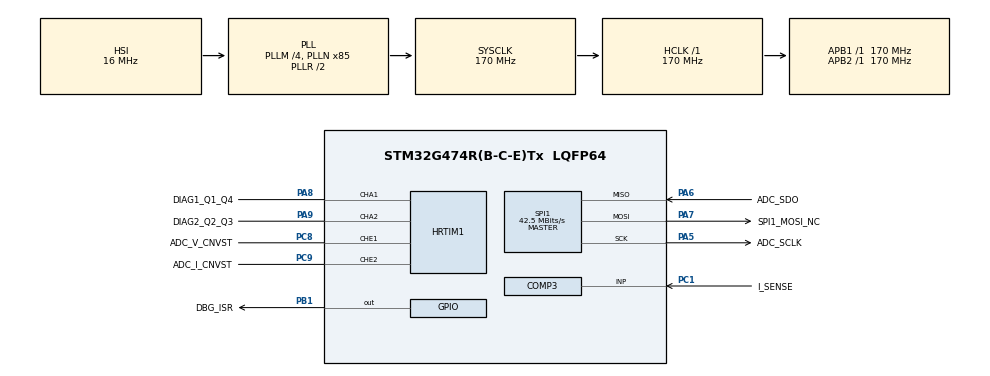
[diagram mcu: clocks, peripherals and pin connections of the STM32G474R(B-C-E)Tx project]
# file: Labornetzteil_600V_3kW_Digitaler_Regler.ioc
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Dma.HRTIM1_E.1.Direction=DMA_MEMORY_TO_PERIPH
Dma.HRTIM1_E.1.EventEnable=DISABLE
Dma.HRTIM1_E.1.Instance=DMA1_Channel1
Dma.HRTIM1_E.1.MemDataAlignment=DMA_MDATAALIGN_HALFWORD
Dma.HRTIM1_E.1.MemInc=DMA_MINC_DISABLE
Dma.HRTIM1_E.1.Mode=DMA_CIRCULAR
Dma.HRTIM1_E.1.PeriphDataAlignment=DMA_PDATAALIGN_HALFWORD
Dma.HRTIM1_E.1.PeriphInc=DMA_PINC_DISABLE
Dma.HRTIM1_E.1.Polarity=HAL_DMAMUX_REQ_GEN_RISING
Dma.HRTIM1_E.1.Priority=DMA_PRIORITY_HIGH
Dma.HRTIM1_E.1.RequestNumber=1
Dma.HRTIM1_E.1.SignalID=NONE
Dma.HRTIM1_E.1.SyncEnable=DISABLE
Dma.HRTIM1_E.1.SyncPolarity=HAL_DMAMUX_SYNC_NO_EVENT
Dma.HRTIM1_E.1.SyncRequestNumber=1
Dma.HRTIM1_E.1.SyncSignalID=NONE
Dma.Request0=SPI1_RX
Dma.Request1=HRTIM1_E
Dma.SPI1_RX.0.Direction=DMA_PERIPH_TO_MEMORY
Dma.SPI1_RX.0.EventEnable=DISABLE
Dma.SPI1_RX.0.Instance=DMA1_Channel2
Dma.SPI1_RX.0.MemDataAlignment=DMA_MDATAALIGN_HALFWORD
Dma.SPI1_RX.0.MemInc=DMA_MINC_ENABLE
Dma.SPI1_RX.0.Mode=DMA_CIRCULAR
Dma.SPI1_RX.0.PeriphDataAlignment=DMA_PDATAALIGN_HALFWORD
Dma.SPI1_RX.0.PeriphInc=DMA_PINC_DISABLE
Dma.SPI1_RX.0.Polarity=HAL_DMAMUX_REQ_GEN_RISING
Dma.SPI1_RX.0.Priority=DMA_PRIORITY_VERY_HIGH
Dma.SPI1_RX.0.RequestNumber=1
Dma.SPI1_RX.0.SignalID=NONE
Dma.SPI1_RX.0.SyncEnable=DISABLE
Dma.SPI1_RX.0.SyncPolarity=HAL_DMAMUX_SYNC_NO_EVENT
Dma.SPI1_RX.0.SyncRequestNumber=1
Dma.SPI1_RX.0.SyncSignalID=NONE
HRTIM1.ADCTrigger_Id1=__NULL
HRTIM1.ADCTrigger_Id10=__NULL
HRTIM1.ADCTrigger_Id2=__NULL
HRTIM1.ADCTrigger_Id3=__NULL
HRTIM1.ADCTrigger_Id4=__NULL
HRTIM1.ADCTrigger_Id5=__NULL
HRTIM1.ADCTrigger_Id6=__NULL
HRTIM1.ADCTrigger_Id7=__NULL
HRTIM1.ADCTrigger_Id8=__NULL
HRTIM1.ADCTrigger_Id9=__NULL
HRTIM1.AutoDelayedMode2-Output_TA1TA2=HRTIM_AUTODELAYEDMODE_REGULAR
HRTIM1.AutoDelayedMode2-Output_TE1TE2=HRTIM_AUTODELAYEDMODE_REGULAR
HRTIM1.BlankingSourceFaultLine5=__NULL
HRTIM1.BurstDMAconfig-Output_TA1TA2=__NULL
HRTIM1.BurstDMAconfig-Output_TE1TE2=__NULL
HRTIM1.BurstMode-Output_TA1TA2=HRTIM_TIMERBURSTMODE_MAINTAINCLOCK
HRTIM1.BurstMode-Output_TE1TE2=HRTIM_TIMERBURSTMODE_MAINTAINCLOCK
HRTIM1.BurstModeEntryDelayed1-Output_TA1TA2=HRTIM_OUTPUTBURSTMODEENTRY_REGULAR
HRTIM1.BurstModeEntryDelayed1-Output_TE1TE2=HRTIM_OUTPUTBURSTMODEENTRY_REGULAR
HRTIM1.BurstModeEntryDelayed2-Output_TA1TA2=HRTIM_OUTPUTBURSTMODEENTRY_REGULAR
HRTIM1.BurstModeEntryDelayed2-Output_TE1TE2=HRTIM_OUTPUTBURSTMODEENTRY_REGULAR
HRTIM1.CaptureUnit1-Output_TA1TA2=__NULL
HRTIM1.CaptureUnit1-Output_TE1TE2=__NULL
HRTIM1.CaptureUnit2-Output_TA1TA2=__NULL
HRTIM1.CaptureUnit2-Output_TE1TE2=__NULL
HRTIM1.ChopperModeEnable1-Output_TA1TA2=HRTIM_OUTPUTCHOPPERMODE_DISABLED
HRTIM1.ChopperModeEnable1-Output_TE1TE2=HRTIM_OUTPUTCHOPPERMODE_DISABLED
HRTIM1.ChopperModeEnable2-Output_TA1TA2=HRTIM_OUTPUTCHOPPERMODE_DISABLED
HRTIM1.ChopperModeEnable2-Output_TE1TE2=HRTIM_OUTPUTCHOPPERMODE_DISABLED
HRTIM1.ChopperModeconfig-Output_TA1TA2=__NULL
HRTIM1.ChopperModeconfig-Output_TE1TE2=__NULL
HRTIM1.CompareUnit1-Output_TA1TA2=HRTIM_COMPAREUNIT_1
HRTIM1.CompareUnit1-Output_TE1TE2=HRTIM_COMPAREUNIT_1
HRTIM1.CompareUnit2-Output_TA1TA2=HRTIM_COMPAREUNIT_2
HRTIM1.CompareUnit2-Output_TE1TE2=HRTIM_COMPAREUNIT_2
HRTIM1.CompareUnit3-Output_TA1TA2=HRTIM_COMPAREUNIT_3
HRTIM1.CompareUnit3-Output_TE1TE2=HRTIM_COMPAREUNIT_3
HRTIM1.CompareUnit4-Output_TA1TA2=__NULL
HRTIM1.CompareUnit4-Output_TE1TE2=__NULL
HRTIM1.CompareValue1-Output_TA1TA2=163
HRTIM1.CompareValue1-Output_TE1TE2=22304
HRTIM1.CompareValue2-Output_TA1TA2=27200
HRTIM1.CompareValue2-Output_TE1TE2=26656
HRTIM1.CompareValue3-Output_TA1TA2=27363
HRTIM1.CompareValue3-Output_TE1TE2=30067
HRTIM1.Configuration_TA=Waveform
HRTIM1.Configuration_TE=Waveform
HRTIM1.CounterFaultLine5=0
HRTIM1.DACSynchro-Output_TA1TA2=HRTIM_DACSYNC_NONE
HRTIM1.DACSynchro-Output_TE1TE2=HRTIM_DACSYNC_NONE
HRTIM1.DMADstAddress-Output_TE1TE2=(uint32_t)&SPI1->DR
HRTIM1.DMARequests1-Output_TE1TE2=HRTIM_TIM_DMA_CMP2
HRTIM1.DMARequests2-Output_TE1TE2=HRTIM_TIM_DMA_CMP3
HRTIM1.DMASize-Output_TE1TE2=0x1
HRTIM1.DMASrcAddress-Output_TE1TE2=(uint32_t)&pwr_spi_dummy
HRTIM1.DeadTimeInsertion-Output_TA1TA2=HRTIM_TIMDEADTIMEINSERTION_DISABLED
HRTIM1.DeadTimeInsertion-Output_TE1TE2=HRTIM_TIMDEADTIMEINSERTION_DISABLED
HRTIM1.Deadtimeconfig-Output_TA1TA2=__NULL
HRTIM1.Deadtimeconfig-Output_TE1TE2=__NULL
HRTIM1.DelayedProtectionMode-Output_TA1TA2=HRTIM_TIMER_A_B_C_DELAYEDPROTECTION_DISABLED
HRTIM1.DelayedProtectionMode-Output_TE1TE2=HRTIM_TIMER_D_E_DELAYEDPROTECTION_DISABLED
HRTIM1.DualChannelDacEnableFake_TA-Output_TA1TA2=HRTIM_TIMER_DCDE_DISABLED
HRTIM1.DualChannelDacEnableFake_TE-Output_TE1TE2=HRTIM_TIMER_DCDE_DISABLED
HRTIM1.Enable=HRTIM_BURSTMODECTL_DISABLED
HRTIM1.Enable_FaultLine5=HRTIM_FAULTMODECTL_ENABLED
HRTIM1.Event1-Output_TA1TA2=__NULL
HRTIM1.Event1-Output_TE1TE2=__NULL
HRTIM1.Event10-Output_TA1TA2=__NULL
HRTIM1.Event10-Output_TE1TE2=__NULL
HRTIM1.Event2-Output_TA1TA2=__NULL
HRTIM1.Event2-Output_TE1TE2=__NULL
HRTIM1.Event3-Output_TA1TA2=__NULL
HRTIM1.Event3-Output_TE1TE2=__NULL
HRTIM1.Event4-Output_TA1TA2=__NULL
HRTIM1.Event4-Output_TE1TE2=__NULL
HRTIM1.Event5-Output_TA1TA2=__NULL
HRTIM1.Event5-Output_TE1TE2=__NULL
HRTIM1.Event6-Output_TA1TA2=__NULL
HRTIM1.Event6-Output_TE1TE2=__NULL
HRTIM1.Event7-Output_TA1TA2=__NULL
HRTIM1.Event7-Output_TE1TE2=__NULL
HRTIM1.Event8-Output_TA1TA2=__NULL
HRTIM1.Event8-Output_TE1TE2=__NULL
HRTIM1.Event9-Output_TA1TA2=__NULL
HRTIM1.Event9-Output_TE1TE2=__NULL
HRTIM1.EventEnableA-Output_TA1TA2=__NULL
HRTIM1.EventEnableA-Output_TE1TE2=__NULL
HRTIM1.Event_EEV1=__NULL
HRTIM1.Event_EEV10=__NULL
HRTIM1.Event_EEV2=__NULL
HRTIM1.Event_EEV3=__NULL
HRTIM1.Event_EEV4=__NULL
HRTIM1.Event_EEV5=__NULL
HRTIM1.Event_EEV6=__NULL
HRTIM1.Event_EEV7=__NULL
HRTIM1.Event_EEV8=__NULL
HRTIM1.Event_EEV9=__NULL
HRTIM1.FaultEnable_Source1-Output_TA1TA2=HRTIM_TIMFAULTENABLE_FAULT5
HRTIM1.FaultLevel1-Output_TA1TA2=HRTIM_OUTPUTFAULTLEVEL_INACTIVE
HRTIM1.FaultLevel1-Output_TE1TE2=HRTIM_OUTPUTFAULTLEVEL_NONE
HRTIM1.FaultLevel2-Output_TA1TA2=HRTIM_OUTPUTFAULTLEVEL_INACTIVE
HRTIM1.FaultLevel2-Output_TE1TE2=HRTIM_OUTPUTFAULTLEVEL_NONE
HRTIM1.FaultLock-Output_TA1TA2=HRTIM_TIMFAULTLOCK_READONLY
HRTIM1.FaultLock-Output_TE1TE2=HRTIM_TIMFAULTLOCK_READWRITE
HRTIM1.Fault_Line1=__NULL
HRTIM1.Fault_Line2=__NULL
HRTIM1.Fault_Line3=__NULL
HRTIM1.Fault_Line4=__NULL
HRTIM1.Fault_Line5=HRTIM_FAULT_5
HRTIM1.Fault_Line6=__NULL
HRTIM1.Filter_FaultLine5=HRTIM_FAULTFILTER_NONE
HRTIM1.GreaterCMP1_TA=HRTIM_TIMERGTCMP1_EQUAL
HRTIM1.GreaterCMP1_TE=HRTIM_TIMERGTCMP1_EQUAL
HRTIM1.GreaterCMP3_TA=HRTIM_TIMERGTCMP3_EQUAL
HRTIM1.GreaterCMP3_TE=HRTIM_TIMERGTCMP3_EQUAL
HRTIM1.HRTIMInterruptResquests1=HRTIM_IT_NONE
HRTIM1.HRTIMInterruptResquests2=HRTIM_IT_NONE
HRTIM1.HRTIMInterruptResquests3=HRTIM_IT_NONE
HRTIM1.HRTIMInterruptResquests4=HRTIM_IT_NONE
HRTIM1.HRTIMInterruptResquests5=HRTIM_IT_NONE
HRTIM1.HRTIMInterruptResquests6=HRTIM_IT_NONE
HRTIM1.HRTIMInterruptResquests7=HRTIM_IT_NONE
HRTIM1.HRTIMInterruptResquests8=HRTIM_IT_NONE
HRTIM1.HRTIMInterruptResquests9=HRTIM_IT_NONE
HRTIM1.IdleLevel1-Output_TA1TA2=HRTIM_OUTPUTIDLELEVEL_INACTIVE
HRTIM1.IdleLevel1-Output_TE1TE2=HRTIM_OUTPUTIDLELEVEL_INACTIVE
HRTIM1.IdleLevel2-Output_TA1TA2=HRTIM_OUTPUTIDLELEVEL_INACTIVE
HRTIM1.IdleLevel2-Output_TE1TE2=HRTIM_OUTPUTIDLELEVEL_INACTIVE
HRTIM1.IdleMode1-Output_TA1TA2=HRTIM_OUTPUTIDLEMODE_NONE
HRTIM1.IdleMode1-Output_TE1TE2=HRTIM_OUTPUTIDLEMODE_NONE
HRTIM1.IdleMode2-Output_TA1TA2=HRTIM_OUTPUTIDLEMODE_NONE
HRTIM1.IdleMode2-Output_TE1TE2=HRTIM_OUTPUTIDLEMODE_NONE
HRTIM1.InterleavedMode-Output_TA1TA2=HRTIM_INTERLEAVED_MODE_DISABLED
HRTIM1.InterleavedMode-Output_TE1TE2=HRTIM_INTERLEAVED_MODE_DISABLED
HRTIM1.Lock_FaultLine5=HRTIM_FAULTLOCK_READWRITE
HRTIM1.ModeTimeBase-Output_TA1TA2=HRTIM_MODE_CONTINUOUS
HRTIM1.ModeTimeBase-Output_TE1TE2=HRTIM_MODE_CONTINUOUS
HRTIM1.NumberDMARequests_TA=0
HRTIM1.NumberDMARequests_TE=2
HRTIM1.NumberFaultEnable-Output_TA1TA2=1
HRTIM1.NumberFaultEnable-Output_TE1TE2=0
HRTIM1.NumberInterruptRequests-Output_TA1TA2=0
HRTIM1.NumberInterruptRequests-Output_TE1TE2=0
HRTIM1.NumberResetSource1-Output_TA1TA2=1
HRTIM1.NumberResetSource1-Output_TE1TE2=1
HRTIM1.NumberResetSource2_TA=1
HRTIM1.NumberResetSource2_TE=1
HRTIM1.NumberResetTrigger-Output_TA1TA2=0
HRTIM1.NumberResetTrigger-Output_TE1TE2=0
HRTIM1.NumberSetSource1-Output_TA1TA2=1
HRTIM1.NumberSetSource1-Output_TE1TE2=1
HRTIM1.NumberSetSource2_TA=1
HRTIM1.NumberSetSource2_TE=1
HRTIM1.NumberUpdateTrigger-Output_TA1TA2=0
HRTIM1.NumberUpdateTrigger-Output_TE1TE2=0
HRTIM1.Output1-Output_TA1TA2=HRTIM_OUTPUT_TA1
HRTIM1.Output1-Output_TE1TE2=HRTIM_OUTPUT_TE1
HRTIM1.Output2-Output_TA1TA2=HRTIM_OUTPUT_TA2
HRTIM1.Output2-Output_TE1TE2=HRTIM_OUTPUT_TE2
HRTIM1.Periode_TA=54400
HRTIM1.Periode_TE=54400
HRTIM1.Polarity1-Output_TA1TA2=HRTIM_OUTPUTPOLARITY_HIGH
HRTIM1.Polarity1-Output_TE1TE2=HRTIM_OUTPUTPOLARITY_HIGH
HRTIM1.Polarity2-Output_TA1TA2=HRTIM_OUTPUTPOLARITY_HIGH
HRTIM1.Polarity2-Output_TE1TE2=HRTIM_OUTPUTPOLARITY_HIGH
HRTIM1.Polarity_FaultLine5=HRTIM_FAULTPOLARITY_HIGH
HRTIM1.PreloadEnable-Output_TA1TA2=HRTIM_PRELOAD_ENABLED
HRTIM1.PreloadEnable-Output_TE1TE2=HRTIM_PRELOAD_ENABLED
HRTIM1.PrescalerFault=HRTIM_FAULTPRESCALER_DIV1
HRTIM1.PrescalerRatio_TA=HRTIM_PRESCALERRATIO_MUL32
HRTIM1.PrescalerRatio_TE=HRTIM_PRESCALERRATIO_MUL32
HRTIM1.PushPull-Output_TA1TA2=HRTIM_TIMPUSHPULLMODE_DISABLED
HRTIM1.PushPull-Output_TE1TE2=HRTIM_TIMPUSHPULLMODE_DISABLED
HRTIM1.ReSyncUpdate-Output_TA1TA2=HRTIM_TIMERESYNC_UPDATE_UNCONDITIONAL
HRTIM1.ReSyncUpdate-Output_TE1TE2=HRTIM_TIMERESYNC_UPDATE_UNCONDITIONAL
HRTIM1.RepetitionUpdate-Output_TA1TA2=HRTIM_UPDATEONREPETITION_DISABLED
HRTIM1.RepetitionUpdate-Output_TE1TE2=HRTIM_UPDATEONREPETITION_DISABLED
HRTIM1.ResetModeFaultLine5=HRTIM_FAULTCOUNTERRST_UNCONDITIONAL
HRTIM1.ResetOnSync-Output_TA1TA2=HRTIM_SYNCRESET_DISABLED
HRTIM1.ResetOnSync-Output_TE1TE2=HRTIM_SYNCRESET_DISABLED
HRTIM1.ResetOutput1_Source1-Output_TA1TA2=HRTIM_OUTPUTRESET_TIMCMP1
HRTIM1.ResetOutput1_Source1-Output_TE1TE2=HRTIM_OUTPUTRESET_TIMCMP2
HRTIM1.ResetOutput2_Source1-Output_TA1TA2=HRTIM_OUTPUTRESET_TIMCMP3
HRTIM1.ResetOutput2_Source1-Output_TE1TE2=HRTIM_OUTPUTRESET_TIMCMP3
HRTIM1.ResetUpdate-Output_TA1TA2=HRTIM_TIMUPDATEONRESET_ENABLED
HRTIM1.ResetUpdate-Output_TE1TE2=HRTIM_TIMUPDATEONRESET_ENABLED
HRTIM1.SetOutput1_Source1-Output_TA1TA2=HRTIM_OUTPUTSET_TIMPER
HRTIM1.SetOutput1_Source1-Output_TE1TE2=HRTIM_OUTPUTSET_TIMCMP1
HRTIM1.SetOutput2_Source1-Output_TA1TA2=HRTIM_OUTPUTSET_TIMCMP2
HRTIM1.SetOutput2_Source1-Output_TE1TE2=HRTIM_OUTPUTSET_TIMCMP1
HRTIM1.Source_FaultLine5=HRTIM_FAULTSOURCE_INTERNAL
HRTIM1.StartOnSync-Output_TA1TA2=HRTIM_SYNCSTART_DISABLED
HRTIM1.StartOnSync-Output_TE1TE2=HRTIM_SYNCSTART_DISABLED
HRTIM1.SwapA=__NULL
HRTIM1.SwapE=__NULL
HRTIM1.SyncOptions=HRTIM_SYNCOPTION_NONE
HRTIM1.TimerIdx-Output_TA1TA2=HRTIM_TIMERINDEX_TIMER_A
HRTIM1.TimerIdx-Output_TE1TE2=HRTIM_TIMERINDEX_TIMER_E
HRTIM1.TrigHalf_TA=HRTIM_TIMERTRIGHALF_DISABLED
HRTIM1.TrigHalf_TE=HRTIM_TIMERTRIGHALF_DISABLED
HRTIM1.UpDownMode-Output_TA1TA2=HRTIM_TIMERUPDOWNMODE_UP
HRTIM1.UpDownMode-Output_TE1TE2=HRTIM_TIMERUPDOWNMODE_UP
HRTIM1.UpdateGating-Output_TA1TA2=HRTIM_UPDATEGATING_INDEPENDENT
HRTIM1.UpdateGating-Output_TE1TE2=HRTIM_UPDATEGATING_INDEPENDENT
Mcu.Family=STM32G4
Mcu.Name=STM32G474R(B-C-E)Tx
Mcu.Package=LQFP64
NVIC.DMA1_Channel1_IRQn=true\:2\:0\:false\:false\:true\:false\:true\:true
NVIC.DMA1_Channel2_IRQn=true\:0\:0\:false\:false\:false\:false\:false\:true
NVIC.PriorityGroup=NVIC_PRIORITYGROUP_4
PA13.Mode=Serial_Wire
PA13.Signal=SYS_JTMS-SWDIO
PA14.Mode=Serial_Wire
PA14.Signal=SYS_JTCK-SWCLK
PA5.GPIO_Label=ADC_SCLK
PA5.GPIO_Speed=GPIO_SPEED_FREQ_VERY_HIGH
PA5.Mode=Full_Duplex_Master
PA5.Signal=SPI1_SCK
PA6.GPIO_Label=ADC_SDO
PA6.GPIO_PuPd=GPIO_PULLUP
PA6.GPIO_Speed=GPIO_SPEED_FREQ_VERY_HIGH
PA6.Mode=Full_Duplex_Master
PA6.Signal=SPI1_MISO
PA7.GPIO_Label=SPI1_MOSI_NC
PA7.Mode=Full_Duplex_Master
PA7.Signal=SPI1_MOSI
PA8.GPIO_Label=DIAG1_Q1_Q4
PA8.GPIO_Speed=GPIO_SPEED_FREQ_VERY_HIGH
PA8.Mode=Output_TA1TA2
PA8.Signal=HRTIM1_CHA1
PA9.GPIO_Label=DIAG2_Q2_Q3
PA9.GPIO_Speed=GPIO_SPEED_FREQ_VERY_HIGH
PA9.Mode=Output_TA1TA2
PA9.Signal=HRTIM1_CHA2
PB1.GPIO_Label=DBG_ISR
PB1.GPIO_Speed=GPIO_SPEED_FREQ_VERY_HIGH
PB1.Signal=GPIO_Output
PC1.GPIO_Label=I_SENSE
PC1.Mode=INP
PC1.Signal=COMP3_INP
PC8.GPIO_Label=ADC_V_CNVST
PC8.GPIO_Speed=GPIO_SPEED_FREQ_VERY_HIGH
PC8.Mode=Output_TE1TE2
PC8.Signal=HRTIM1_CHE1
PC9.GPIO_Label=ADC_I_CNVST
PC9.GPIO_Speed=GPIO_SPEED_FREQ_VERY_HIGH
PC9.Mode=Output_TE1TE2
PC9.Signal=HRTIM1_CHE2
ProjectManager.HeapSize=0x200
ProjectManager.StackSize=0x400
ProjectManager.TargetToolchain=STM32CubeIDE
RCC.ADC12Freq_Value=170000000
RCC.ADC345Freq_Value=170000000
RCC.AHBFreq_Value=170000000
RCC.APB1Freq_Value=170000000
RCC.APB1TimFreq_Value=170000000
RCC.APB2Freq_Value=170000000
RCC.APB2TimFreq_Value=170000000
RCC.CortexFreq_Value=170000000
RCC.EXTERNAL_CLOCK_VALUE=12288000
RCC.HCLKFreq_Value=170000000
RCC.HSE_VALUE=8000000
RCC.HSI48_VALUE=48000000
RCC.HSI_VALUE=16000000
RCC.LSE_VALUE=32768
RCC.PLLM=RCC_PLLM_DIV4
RCC.PLLN=85
RCC.PLLSourceVirtual=RCC_PLLSOURCE_HSI
RCC.SYSCLKFreq_VALUE=170000000
RCC.SYSCLKSource=RCC_SYSCLKSOURCE_PLLCLK
RCC.USBFreq_Value=170000000
RCC.VCOOutputFreq_Value=340000000
SPI1.BaudRatePrescaler=SPI_BAUDRATEPRESCALER_4
SPI1.CLKPhase=SPI_PHASE_2EDGE
SPI1.CLKPolarity=SPI_POLARITY_LOW
SPI1.CRCCalculation=SPI_CRCCALCULATION_DISABLE
SPI1.CalculateBaudRate=42.5 MBits/s
SPI1.DataSize=SPI_DATASIZE_16BIT
SPI1.Direction=SPI_DIRECTION_2LINES
SPI1.FirstBit=SPI_FIRSTBIT_MSB
SPI1.Mode=SPI_MODE_MASTER
SPI1.NSS=SPI_NSS_SOFT
SPI1.TIMode=SPI_TIMODE_DISABLE
SPI1.VirtualType=VM_MASTER
VP_COMP3_VS_DAC3OUT1.Mode=INM_DAC3OUT1
VP_DAC3_VS_DACI1.Mode=DAC_OUT1_Int
VP_SYS_VS_DBSignals.Mode=DisableDeadBatterySignals
board=custom

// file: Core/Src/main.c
/* USER CODE BEGIN Header */
/**
  ******************************************************************************
  * @file           : main.c
  * @brief          : Main program body
  ******************************************************************************
  * @attention
  *
  * Copyright (c) 2026 STMicroelectronics.
  * All rights reserved.
  *
  * This software is licensed under terms that can be found in the LICENSE file
  * in the root directory of this software component.
  * If no LICENSE file comes with this software, it is provided AS-IS.
  *
  ******************************************************************************
  */
/* USER CODE END Header */
#include "main.h"

/* USER CODE BEGIN Includes */
#include "pwr_ctrl.h"   /* also declares pwr_spi_dummy, used in MX_HRTIM1_Init() */
/* USER CODE END Includes */

COMP_HandleTypeDef hcomp3;

DAC_HandleTypeDef hdac3;

HRTIM_HandleTypeDef hhrtim1;
DMA_HandleTypeDef hdma_hrtim1_e;

SPI_HandleTypeDef hspi1;
DMA_HandleTypeDef hdma_spi1_rx;

void SystemClock_Config(void);
static void MX_GPIO_Init(void);
static void MX_DMA_Init(void);
static void MX_HRTIM1_Init(void);
static void MX_SPI1_Init(void);
static void MX_COMP3_Init(void);
static void MX_DAC3_Init(void);

int main(void)
{

  /* MCU Configuration--------------------------------------------------------*/

  /* Reset of all peripherals, Initializes the Flash interface and the Systick. */
  HAL_Init();

  /* Configure the system clock */
  SystemClock_Config();

  /* Initialize all configured peripherals */
  MX_GPIO_Init();
  MX_DMA_Init();
  MX_HRTIM1_Init();
  MX_SPI1_Init();
  MX_COMP3_Init();
  MX_DAC3_Init();
  /* USER CODE BEGIN 2 */

  /* Hardware OCP (DAC3 -> COMP3 -> HRTIM FLT5) armed at PWR_OCP_HW_A,
   * ADC recalibration (~0.6 s), DMA chain start, HRTIM counters start.
   * Afterwards both ADCs are sampled every period, the bridge stays OFF. */
  pwr_init(&hhrtim1, &hspi1, &hcomp3, &hdac3);

  pwr_set_current(1.0f);    /* [A] current limit                          */
  pwr_set_voltage(5.0f);    /* [V] ramps at PWR_VREF_SLEW_V_PER_S         */

  /* Bring-up: enable the bridge deliberately (debugger or command), e.g.*/
  pwr_output_on();

  /* USER CODE END 2 */

  /* Infinite loop */
  while (1)
  {

    /* USER CODE BEGIN 3 */
    const pwr_status_t *st = pwr_status();
    if (st->state == PWR_STATE_FAULT)
    {
      /* report st->fault (PWR_FAULT_x), then e.g.:
       * pwr_clear_fault(); (void)pwr_output_on();                          */
    }
  }
  /* USER CODE END 3 */
}

void SystemClock_Config(void)
{
  RCC_OscInitTypeDef RCC_OscInitStruct = {0};
  RCC_ClkInitTypeDef RCC_ClkInitStruct = {0};

  /** Configure the main internal regulator output voltage
  */
  HAL_PWREx_ControlVoltageScaling(PWR_REGULATOR_VOLTAGE_SCALE1_BOOST);

  /** Initializes the RCC Oscillators according to the specified parameters
  * in the RCC_OscInitTypeDef structure.
  */
  RCC_OscInitStruct.OscillatorType = RCC_OSCILLATORTYPE_HSI;
  RCC_OscInitStruct.HSIState = RCC_HSI_ON;
  RCC_OscInitStruct.HSICalibrationValue = RCC_HSICALIBRATION_DEFAULT;
  RCC_OscInitStruct.PLL.PLLState = RCC_PLL_ON;
  RCC_OscInitStruct.PLL.PLLSource = RCC_PLLSOURCE_HSI;
  RCC_OscInitStruct.PLL.PLLM = RCC_PLLM_DIV4;
  RCC_OscInitStruct.PLL.PLLN = 85;
  RCC_OscInitStruct.PLL.PLLP = RCC_PLLP_DIV2;
  RCC_OscInitStruct.PLL.PLLQ = RCC_PLLQ_DIV2;
  RCC_OscInitStruct.PLL.PLLR = RCC_PLLR_DIV2;
  if (HAL_RCC_OscConfig(&RCC_OscInitStruct) != HAL_OK)
  {
    Error_Handler();
  }

  /** Initializes the CPU, AHB and APB buses clocks
  */
  RCC_ClkInitStruct.ClockType = RCC_CLOCKTYPE_HCLK|RCC_CLOCKTYPE_SYSCLK
                              |RCC_CLOCKTYPE_PCLK1|RCC_CLOCKTYPE_PCLK2;
  RCC_ClkInitStruct.SYSCLKSource = RCC_SYSCLKSOURCE_PLLCLK;
  RCC_ClkInitStruct.AHBCLKDivider = RCC_SYSCLK_DIV1;
  RCC_ClkInitStruct.APB1CLKDivider = RCC_HCLK_DIV1;
  RCC_ClkInitStruct.APB2CLKDivider = RCC_HCLK_DIV1;

  if (HAL_RCC_ClockConfig(&RCC_ClkInitStruct, FLASH_LATENCY_4) != HAL_OK)
  {
    Error_Handler();
  }
}

static void MX_COMP3_Init(void)
{

  hcomp3.Instance = COMP3;
  hcomp3.Init.InputPlus = COMP_INPUT_PLUS_IO2;
  hcomp3.Init.InputMinus = COMP_INPUT_MINUS_DAC3_CH1;
  hcomp3.Init.OutputPol = COMP_OUTPUTPOL_NONINVERTED;
  hcomp3.Init.Hysteresis = COMP_HYSTERESIS_NONE;
  hcomp3.Init.BlankingSrce = COMP_BLANKINGSRC_NONE;
  hcomp3.Init.TriggerMode = COMP_TRIGGERMODE_NONE;
  if (HAL_COMP_Init(&hcomp3) != HAL_OK)
  {
    Error_Handler();
  }

}

static void MX_DAC3_Init(void)
{

  DAC_ChannelConfTypeDef sConfig = {0};

  /** DAC Initialization
  */
  hdac3.Instance = DAC3;
  if (HAL_DAC_Init(&hdac3) != HAL_OK)
  {
    Error_Handler();
  }

  /** DAC channel OUT1 config
  */
  sConfig.DAC_HighFrequency = DAC_HIGH_FREQUENCY_INTERFACE_MODE_AUTOMATIC;
  sConfig.DAC_DMADoubleDataMode = DISABLE;
  sConfig.DAC_SignedFormat = DISABLE;
  sConfig.DAC_SampleAndHold = DAC_SAMPLEANDHOLD_DISABLE;
  sConfig.DAC_Trigger = DAC_TRIGGER_NONE;
  sConfig.DAC_Trigger2 = DAC_TRIGGER_NONE;
  sConfig.DAC_OutputBuffer = DAC_OUTPUTBUFFER_DISABLE;
  sConfig.DAC_ConnectOnChipPeripheral = DAC_CHIPCONNECT_INTERNAL;
  sConfig.DAC_UserTrimming = DAC_TRIMMING_FACTORY;
  if (HAL_DAC_ConfigChannel(&hdac3, &sConfig, DAC_CHANNEL_1) != HAL_OK)
  {
    Error_Handler();
  }

}

static void MX_HRTIM1_Init(void)
{

  HRTIM_FaultBlankingCfgTypeDef pFaultBlkCfg = {0};
  HRTIM_FaultCfgTypeDef pFaultCfg = {0};
  HRTIM_TimeBaseCfgTypeDef pTimeBaseCfg = {0};
  HRTIM_TimerCtlTypeDef pTimerCtl = {0};
  HRTIM_TimerCfgTypeDef pTimerCfg = {0};
  HRTIM_CompareCfgTypeDef pCompareCfg = {0};
  HRTIM_OutputCfgTypeDef pOutputCfg = {0};

  hhrtim1.Instance = HRTIM1;
  hhrtim1.Init.HRTIMInterruptResquests = HRTIM_IT_NONE;
  hhrtim1.Init.SyncOptions = HRTIM_SYNCOPTION_NONE;
  if (HAL_HRTIM_Init(&hhrtim1) != HAL_OK)
  {
    Error_Handler();
  }
  if (HAL_HRTIM_DLLCalibrationStart(&hhrtim1, HRTIM_CALIBRATIONRATE_3) != HAL_OK)
  {
    Error_Handler();
  }
  if (HAL_HRTIM_PollForDLLCalibration(&hhrtim1, 10) != HAL_OK)
  {
    Error_Handler();
  }
  if (HAL_HRTIM_FaultPrescalerConfig(&hhrtim1, HRTIM_FAULTPRESCALER_DIV1) != HAL_OK)
  {
    Error_Handler();
  }
  pFaultBlkCfg.Threshold = 0;
  pFaultBlkCfg.ResetMode = HRTIM_FAULTCOUNTERRST_UNCONDITIONAL;
  if (HAL_HRTIM_FaultCounterConfig(&hhrtim1, HRTIM_FAULT_5, &pFaultBlkCfg) != HAL_OK)
  {
    Error_Handler();
  }
  if (HAL_HRTIM_FaultCounterConfig(&hhrtim1, HRTIM_FAULT_5, &pFaultBlkCfg) != HAL_OK)
  {
    Error_Handler();
  }
  pFaultCfg.Source = HRTIM_FAULTSOURCE_INTERNAL;
  pFaultCfg.Polarity = HRTIM_FAULTPOLARITY_HIGH;
  pFaultCfg.Filter = HRTIM_FAULTFILTER_NONE;
  pFaultCfg.Lock = HRTIM_FAULTLOCK_READWRITE;
  if (HAL_HRTIM_FaultConfig(&hhrtim1, HRTIM_FAULT_5, &pFaultCfg) != HAL_OK)
  {
    Error_Handler();
  }
  HAL_HRTIM_FaultModeCtl(&hhrtim1, HRTIM_FAULT_5, HRTIM_FAULTMODECTL_ENABLED);
  pTimeBaseCfg.Period = 54400;
  pTimeBaseCfg.RepetitionCounter = 0x00;
  pTimeBaseCfg.PrescalerRatio = HRTIM_PRESCALERRATIO_MUL32;
  pTimeBaseCfg.Mode = HRTIM_MODE_CONTINUOUS;
  if (HAL_HRTIM_TimeBaseConfig(&hhrtim1, HRTIM_TIMERINDEX_TIMER_A, &pTimeBaseCfg) != HAL_OK)
  {
    Error_Handler();
  }
  pTimerCtl.UpDownMode = HRTIM_TIMERUPDOWNMODE_UP;
  pTimerCtl.TrigHalf = HRTIM_TIMERTRIGHALF_DISABLED;
  pTimerCtl.GreaterCMP3 = HRTIM_TIMERGTCMP3_EQUAL;
  pTimerCtl.GreaterCMP1 = HRTIM_TIMERGTCMP1_EQUAL;
  pTimerCtl.DualChannelDacEnable = HRTIM_TIMER_DCDE_DISABLED;
  if (HAL_HRTIM_WaveformTimerControl(&hhrtim1, HRTIM_TIMERINDEX_TIMER_A, &pTimerCtl) != HAL_OK)
  {
    Error_Handler();
  }
  pTimerCfg.InterruptRequests = HRTIM_TIM_IT_NONE;
  pTimerCfg.DMARequests = HRTIM_TIM_DMA_NONE;
  pTimerCfg.DMASrcAddress = 0x0000;
  pTimerCfg.DMADstAddress = 0x0000;
  pTimerCfg.DMASize = 0x1;
  pTimerCfg.HalfModeEnable = HRTIM_HALFMODE_DISABLED;
  pTimerCfg.InterleavedMode = HRTIM_INTERLEAVED_MODE_DISABLED;
  pTimerCfg.StartOnSync = HRTIM_SYNCSTART_DISABLED;
  pTimerCfg.ResetOnSync = HRTIM_SYNCRESET_DISABLED;
  pTimerCfg.DACSynchro = HRTIM_DACSYNC_NONE;
  pTimerCfg.PreloadEnable = HRTIM_PRELOAD_ENABLED;
  pTimerCfg.UpdateGating = HRTIM_UPDATEGATING_INDEPENDENT;
  pTimerCfg.BurstMode = HRTIM_TIMERBURSTMODE_MAINTAINCLOCK;
  pTimerCfg.RepetitionUpdate = HRTIM_UPDATEONREPETITION_DISABLED;
  pTimerCfg.PushPull = HRTIM_TIMPUSHPULLMODE_DISABLED;
  pTimerCfg.FaultEnable = HRTIM_TIMFAULTENABLE_FAULT5;
  pTimerCfg.FaultLock = HRTIM_TIMFAULTLOCK_READONLY;
  pTimerCfg.DeadTimeInsertion = HRTIM_TIMDEADTIMEINSERTION_DISABLED;
  pTimerCfg.DelayedProtectionMode = HRTIM_TIMER_A_B_C_DELAYEDPROTECTION_DISABLED;
  pTimerCfg.UpdateTrigger = HRTIM_TIMUPDATETRIGGER_NONE;
  pTimerCfg.ResetTrigger = HRTIM_TIMRESETTRIGGER_NONE;
  pTimerCfg.ResetUpdate = HRTIM_TIMUPDATEONRESET_ENABLED;
  pTimerCfg.ReSyncUpdate = HRTIM_TIMERESYNC_UPDATE_UNCONDITIONAL;
  if (HAL_HRTIM_WaveformTimerConfig(&hhrtim1, HRTIM_TIMERINDEX_TIMER_A, &pTimerCfg) != HAL_OK)
  {
    Error_Handler();
  }
  pTimerCfg.DMARequests = HRTIM_TIM_DMA_CMP2|HRTIM_TIM_DMA_CMP3;
  pTimerCfg.DMASrcAddress = (uint32_t)&pwr_spi_dummy;
  pTimerCfg.DMADstAddress = (uint32_t)&SPI1->DR;
  pTimerCfg.FaultEnable = HRTIM_TIMFAULTENABLE_NONE;
  pTimerCfg.FaultLock = HRTIM_TIMFAULTLOCK_READWRITE;
  pTimerCfg.DelayedProtectionMode = HRTIM_TIMER_D_E_DELAYEDPROTECTION_DISABLED;
  if (HAL_HRTIM_WaveformTimerConfig(&hhrtim1, HRTIM_TIMERINDEX_TIMER_E, &pTimerCfg) != HAL_OK)
  {
    Error_Handler();
  }
  pCompareCfg.CompareValue = 163;
  if (HAL_HRTIM_WaveformCompareConfig(&hhrtim1, HRTIM_TIMERINDEX_TIMER_A, HRTIM_COMPAREUNIT_1, &pCompareCfg) != HAL_OK)
  {
    Error_Handler();
  }
  pCompareCfg.CompareValue = 27200;
  pCompareCfg.AutoDelayedMode = HRTIM_AUTODELAYEDMODE_REGULAR;
  pCompareCfg.AutoDelayedTimeout = 0x0000;

  if (HAL_HRTIM_WaveformCompareConfig(&hhrtim1, HRTIM_TIMERINDEX_TIMER_A, HRTIM_COMPAREUNIT_2, &pCompareCfg) != HAL_OK)
  {
    Error_Handler();
  }
  pCompareCfg.CompareValue = 27363;
  if (HAL_HRTIM_WaveformCompareConfig(&hhrtim1, HRTIM_TIMERINDEX_TIMER_A, HRTIM_COMPAREUNIT_3, &pCompareCfg) != HAL_OK)
  {
    Error_Handler();
  }
  pOutputCfg.Polarity = HRTIM_OUTPUTPOLARITY_HIGH;
  pOutputCfg.SetSource = HRTIM_OUTPUTSET_TIMPER;
  pOutputCfg.ResetSource = HRTIM_OUTPUTRESET_TIMCMP1;
  pOutputCfg.IdleMode = HRTIM_OUTPUTIDLEMODE_NONE;
  pOutputCfg.IdleLevel = HRTIM_OUTPUTIDLELEVEL_INACTIVE;
  pOutputCfg.FaultLevel = HRTIM_OUTPUTFAULTLEVEL_INACTIVE;
  pOutputCfg.ChopperModeEnable = HRTIM_OUTPUTCHOPPERMODE_DISABLED;
  pOutputCfg.BurstModeEntryDelayed = HRTIM_OUTPUTBURSTMODEENTRY_REGULAR;
  if (HAL_HRTIM_WaveformOutputConfig(&hhrtim1, HRTIM_TIMERINDEX_TIMER_A, HRTIM_OUTPUT_TA1, &pOutputCfg) != HAL_OK)
  {
    Error_Handler();
  }
  pOutputCfg.SetSource = HRTIM_OUTPUTSET_TIMCMP1;
  pOutputCfg.ResetSource = HRTIM_OUTPUTRESET_TIMCMP2;
  pOutputCfg.FaultLevel = HRTIM_OUTPUTFAULTLEVEL_NONE;
  if (HAL_HRTIM_WaveformOutputConfig(&hhrtim1, HRTIM_TIMERINDEX_TIMER_E, HRTIM_OUTPUT_TE1, &pOutputCfg) != HAL_OK)
  {
    Error_Handler();
  }
  pOutputCfg.SetSource = HRTIM_OUTPUTSET_TIMCMP2;
  pOutputCfg.ResetSource = HRTIM_OUTPUTRESET_TIMCMP3;
  pOutputCfg.FaultLevel = HRTIM_OUTPUTFAULTLEVEL_INACTIVE;
  if (HAL_HRTIM_WaveformOutputConfig(&hhrtim1, HRTIM_TIMERINDEX_TIMER_A, HRTIM_OUTPUT_TA2, &pOutputCfg) != HAL_OK)
  {
    Error_Handler();
  }
  pOutputCfg.SetSource = HRTIM_OUTPUTSET_TIMCMP1;
  pOutputCfg.FaultLevel = HRTIM_OUTPUTFAULTLEVEL_NONE;
  if (HAL_HRTIM_WaveformOutputConfig(&hhrtim1, HRTIM_TIMERINDEX_TIMER_E, HRTIM_OUTPUT_TE2, &pOutputCfg) != HAL_OK)
  {
    Error_Handler();
  }
  if (HAL_HRTIM_TimeBaseConfig(&hhrtim1, HRTIM_TIMERINDEX_TIMER_E, &pTimeBaseCfg) != HAL_OK)
  {
    Error_Handler();
  }
  if (HAL_HRTIM_WaveformTimerControl(&hhrtim1, HRTIM_TIMERINDEX_TIMER_E, &pTimerCtl) != HAL_OK)
  {
    Error_Handler();
  }
  pCompareCfg.CompareValue = 22304;
  if (HAL_HRTIM_WaveformCompareConfig(&hhrtim1, HRTIM_TIMERINDEX_TIMER_E, HRTIM_COMPAREUNIT_1, &pCompareCfg) != HAL_OK)
  {
    Error_Handler();
  }
  pCompareCfg.CompareValue = 26656;

  if (HAL_HRTIM_WaveformCompareConfig(&hhrtim1, HRTIM_TIMERINDEX_TIMER_E, HRTIM_COMPAREUNIT_2, &pCompareCfg) != HAL_OK)
  {
    Error_Handler();
  }
  pCompareCfg.CompareValue = 30067;
  if (HAL_HRTIM_WaveformCompareConfig(&hhrtim1, HRTIM_TIMERINDEX_TIMER_E, HRTIM_COMPAREUNIT_3, &pCompareCfg) != HAL_OK)
  {
    Error_Handler();
  }
  HAL_HRTIM_MspPostInit(&hhrtim1);

}

static void MX_SPI1_Init(void)
{

  /* SPI1 parameter configuration*/
  hspi1.Instance = SPI1;
  hspi1.Init.Mode = SPI_MODE_MASTER;
  hspi1.Init.Direction = SPI_DIRECTION_2LINES;
  hspi1.Init.DataSize = SPI_DATASIZE_16BIT;
  hspi1.Init.CLKPolarity = SPI_POLARITY_LOW;
  hspi1.Init.CLKPhase = SPI_PHASE_2EDGE;
  hspi1.Init.NSS = SPI_NSS_SOFT;
  hspi1.Init.BaudRatePrescaler = SPI_BAUDRATEPRESCALER_4;
  hspi1.Init.FirstBit = SPI_FIRSTBIT_MSB;
  hspi1.Init.TIMode = SPI_TIMODE_DISABLE;
  hspi1.Init.CRCCalculation = SPI_CRCCALCULATION_DISABLE;
  hspi1.Init.CRCPolynomial = 7;
  hspi1.Init.CRCLength = SPI_CRC_LENGTH_DATASIZE;
  hspi1.Init.NSSPMode = SPI_NSS_PULSE_DISABLE;
  if (HAL_SPI_Init(&hspi1) != HAL_OK)
  {
    Error_Handler();
  }

}

static void MX_DMA_Init(void)
{

  /* DMA controller clock enable */
  __HAL_RCC_DMAMUX1_CLK_ENABLE();
  __HAL_RCC_DMA1_CLK_ENABLE();

  /* DMA interrupt init */
  /* DMA1_Channel1_IRQn interrupt configuration */
  HAL_NVIC_SetPriority(DMA1_Channel1_IRQn, 2, 0);
  HAL_NVIC_EnableIRQ(DMA1_Channel1_IRQn);
  /* DMA1_Channel2_IRQn interrupt configuration */
  HAL_NVIC_SetPriority(DMA1_Channel2_IRQn, 0, 0);
  HAL_NVIC_EnableIRQ(DMA1_Channel2_IRQn);

}

static void MX_GPIO_Init(void)
{
  GPIO_InitTypeDef GPIO_InitStruct = {0};

  /* GPIO Ports Clock Enable */
  __HAL_RCC_GPIOC_CLK_ENABLE();
  __HAL_RCC_GPIOA_CLK_ENABLE();
  __HAL_RCC_GPIOB_CLK_ENABLE();

  /*Configure GPIO pin Output Level */
  HAL_GPIO_WritePin(DBG_ISR_GPIO_Port, DBG_ISR_Pin, GPIO_PIN_RESET);

  /*Configure GPIO pin : DBG_ISR_Pin */
  GPIO_InitStruct.Pin = DBG_ISR_Pin;
  GPIO_InitStruct.Mode = GPIO_MODE_OUTPUT_PP;
  GPIO_InitStruct.Pull = GPIO_NOPULL;
  GPIO_InitStruct.Speed = GPIO_SPEED_FREQ_VERY_HIGH;
  HAL_GPIO_Init(DBG_ISR_GPIO_Port, &GPIO_InitStruct);

}

void Error_Handler(void)
{
  /* USER CODE BEGIN Error_Handler_Debug */
  /* User can add his own implementation to report the HAL error return state */
  pwr_emergency_off();      /* never leave the bridge switching */
  __disable_irq();
  while (1)
  {
  }
  /* USER CODE END Error_Handler_Debug */
}
